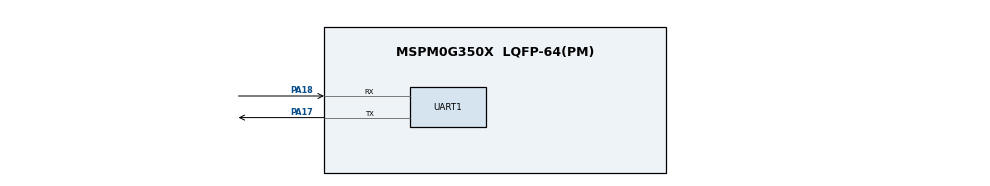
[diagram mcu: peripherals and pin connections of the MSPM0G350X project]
/**
 * @cliArgs --device "MSPM0G350X" --part "Default" --package "LQFP-64(PM)" --product "mspm0_sdk@2.11.00.07"
 * @versions {"tool":"1.26.2+4477"}
 */

/**
 * Import the modules used in this configuration.
 */
const GPIO   = scripting.addModule("/ti/driverlib/GPIO", {}, false);
const GPIO1  = GPIO.addInstance();
const GPIO2  = GPIO.addInstance();
const GPIO3  = GPIO.addInstance();
const PWM    = scripting.addModule("/ti/driverlib/PWM", {}, false);
const PWM1   = PWM.addInstance();
const UART   = scripting.addModule("/ti/driverlib/UART", {}, false);
const UART1  = UART.addInstance();
const SYSCTL = scripting.addModule("/ti/driverlib/SYSCTL");

/**
 * Write custom configuration values to the imported modules.
 */
GPIO1.$name                          = "AD0";
GPIO1.associatedPins.create(3);
GPIO1.associatedPins[0].$name        = "A0";
GPIO1.associatedPins[0].assignedPort = "PORTA";
GPIO1.associatedPins[0].assignedPin  = "0";
GPIO1.associatedPins[1].$name        = "A1";
GPIO1.associatedPins[1].assignedPort = "PORTA";
GPIO1.associatedPins[1].assignedPin  = "1";
GPIO1.associatedPins[2].$name        = "A2";
GPIO1.associatedPins[2].assignedPort = "PORTA";
GPIO1.associatedPins[2].assignedPin  = "2";

const Board = scripting.addModule("/ti/driverlib/Board", {}, false);

GPIO2.$name                          = "out";
GPIO2.associatedPins[0].$name        = "outpin";
GPIO2.associatedPins[0].direction    = "INPUT";
GPIO2.associatedPins[0].assignedPort = "PORTA";
GPIO2.associatedPins[0].assignedPin  = "7";

GPIO3.$name                          = "MOTOR_DIR";
GPIO3.associatedPins.create(4);
GPIO3.associatedPins[0].$name        = "CIN1";
GPIO3.associatedPins[0].assignedPort = "PORTB";
GPIO3.associatedPins[0].assignedPin  = "6";
GPIO3.associatedPins[1].$name        = "CIN2";
GPIO3.associatedPins[1].assignedPort = "PORTB";
GPIO3.associatedPins[1].assignedPin  = "7";
GPIO3.associatedPins[2].$name        = "BIN1";
GPIO3.associatedPins[2].assignedPort = "PORTB";
GPIO3.associatedPins[2].assignedPin  = "8";
GPIO3.associatedPins[3].$name        = "BIN2";
GPIO3.associatedPins[3].assignedPort = "PORTB";
GPIO3.associatedPins[3].assignedPin  = "9";

PWM1.$name                              = "PWM_MOTOR";
PWM1.clockPrescale                      = 64;
PWM1.timerCount                         = 500;
PWM1.PWM_CHANNEL_0.$name                = "ti_driverlib_pwm_PWMTimerCC0";
PWM1.PWM_CHANNEL_1.$name                = "ti_driverlib_pwm_PWMTimerCC1";
PWM1.ccp0PinConfig.$name                = "ti_driverlib_gpio_GPIOPinGeneric0";
PWM1.ccp0PinConfig.direction            = scripting.forceWrite("OUTPUT");
PWM1.ccp0PinConfig.hideOutputInversion  = scripting.forceWrite(false);
PWM1.ccp0PinConfig.onlyInternalResistor = scripting.forceWrite(false);
PWM1.ccp0PinConfig.passedPeripheralType = scripting.forceWrite("Digital");
PWM1.ccp1PinConfig.$name                = "ti_driverlib_gpio_GPIOPinGeneric1";
PWM1.ccp1PinConfig.direction            = scripting.forceWrite("OUTPUT");
PWM1.ccp1PinConfig.hideOutputInversion  = scripting.forceWrite(false);
PWM1.ccp1PinConfig.onlyInternalResistor = scripting.forceWrite(false);
PWM1.ccp1PinConfig.passedPeripheralType = scripting.forceWrite("Digital");

UART1.$name                  = "IMU_UART";
UART1.profile                = "CONFIG_PROFILE_1";
UART1.targetBaudRate         = 9600;
UART1.enableInternalLoopback = false;
UART1.enabledInterrupts      = ["RX"];
UART1.enableFIFO             = false;
UART1.peripheral.$assign     = "UART1";
UART1.peripheral.txPin.$assign = "PA17";
UART1.peripheral.rxPin.$assign = "PA18";

SYSCTL.forceDefaultClkConfig = true;
SYSCTL.clockTreeEn           = true;

/**
 * Pinmux solution for unlocked pins/peripherals. This ensures that minor changes to the automatic solver in a future
 * version of the tool will not impact the pinmux you originally saw.  These lines can be completely deleted in order to
 * re-solve from scratch.
 */
GPIO1.associatedPins[0].pin.$suggestSolution = "PA0";
GPIO1.associatedPins[1].pin.$suggestSolution = "PA1";
GPIO1.associatedPins[2].pin.$suggestSolution = "PA2";
Board.peripheral.$suggestSolution            = "DEBUGSS";
Board.peripheral.swclkPin.$suggestSolution   = "PA20";
Board.peripheral.swdioPin.$suggestSolution   = "PA19";
GPIO2.associatedPins[0].pin.$suggestSolution = "PA7";
GPIO3.associatedPins[0].pin.$suggestSolution = "PB6";
GPIO3.associatedPins[1].pin.$suggestSolution = "PB7";
GPIO3.associatedPins[2].pin.$suggestSolution = "PB8";
GPIO3.associatedPins[3].pin.$suggestSolution = "PB9";
PWM1.peripheral.$suggestSolution             = "TIMA0";
PWM1.peripheral.ccp0Pin.$suggestSolution     = "PA21";
PWM1.peripheral.ccp1Pin.$suggestSolution     = "PA22";
